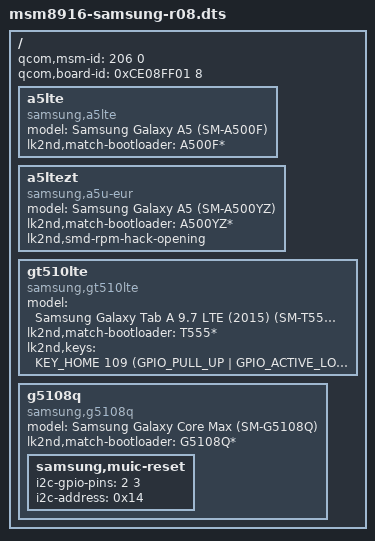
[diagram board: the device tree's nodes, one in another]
// SPDX-License-Identifier: GPL-2.0-only

/dts-v1/;

#include <skeleton.dtsi>
#include <lk2nd.h>

/ {
	// This is used by the bootloader to find the correct DTB
	qcom,msm-id = <206 0>;
	qcom,board-id = <0xCE08FF01 8>;

	a5lte {
		model = "Samsung Galaxy A5 (SM-A500F)";
		compatible = "samsung,a5lte", "qcom,msm8916", "lk2nd,device";
		lk2nd,match-bootloader = "A500F*";
	};

	a5ltezt {
		// In the downstream dts it is called Samsung A5 PROJECT Rev02
		model = "Samsung Galaxy A5 (SM-A500YZ)";
		compatible = "samsung,a5u-eur", "qcom,msm8916", "lk2nd,device";
		lk2nd,match-bootloader = "A500YZ*";
		lk2nd,smd-rpm-hack-opening;
	};

	gt510lte {
		model = "Samsung Galaxy Tab A 9.7 LTE (2015) (SM-T555)";
		compatible = "samsung,gt510lte", "qcom,msm8916", "lk2nd,device";
		lk2nd,match-bootloader = "T555*";

		lk2nd,keys = <KEY_HOME 109 (GPIO_PULL_UP | GPIO_ACTIVE_LOW)>;
	};

	/*
	 * Before building for G5108Q, please comment out all dtbs except
	 *  "$(LOCAL_DIR)/msm8916-samsung-r08.dtb" at './rules.mk'.
	 * g5108q doesn't work with multi-dtbs; only goes into "Download mode".
	 */
	g5108q {
		model = "Samsung Galaxy Core Max (SM-G5108Q)";
		compatible = "samsung,g5108q", "qcom,msm8916", "lk2nd,device";
		lk2nd,match-bootloader = "G5108Q*";

		samsung,muic-reset {
			i2c-gpio-pins = <2 3>;
			i2c-address = <0x14>;
		};
	};
};
